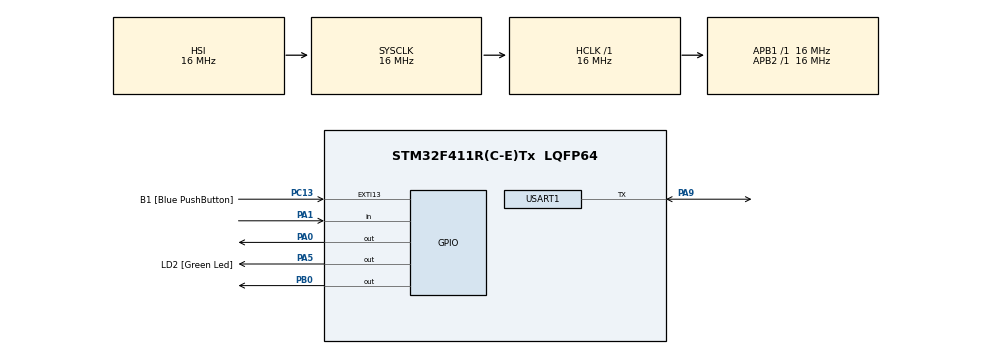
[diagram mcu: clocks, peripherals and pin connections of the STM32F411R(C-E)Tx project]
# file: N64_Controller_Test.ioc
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Mcu.Family=STM32F4
Mcu.Name=STM32F411R(C-E)Tx
Mcu.Package=LQFP64
NVIC.PriorityGroup=NVIC_PRIORITYGROUP_0
PA0-WKUP.GPIO_PuPd=GPIO_PULLUP
PA0-WKUP.Signal=GPIO_Output
PA1.GPIO_PuPd=GPIO_PULLUP
PA1.Signal=GPIO_Input
PA13.Mode=Serial_Wire
PA13.Signal=SYS_JTMS-SWDIO
PA14.Mode=Serial_Wire
PA14.Signal=SYS_JTCK-SWCLK
PA3.GPIO_Label=USART_RX
PA3.Signal=USART2_RX
PA5.GPIO_Label=LD2 [Green Led]
PA5.Signal=GPIO_Output
PA9.Mode=Half_duplex(single_wire_mode)
PA9.Signal=USART1_TX
PB0.GPIO_PuPd=GPIO_PULLUP
PB0.Signal=GPIO_Output
PB3.GPIO_Label=SWO
PB3.Signal=SYS_JTDO-SWO
PC13-ANTI_TAMP.GPIO_Label=B1 [Blue PushButton]
PC13-ANTI_TAMP.GPIO_ModeDefaultEXTI=GPIO_MODE_IT_FALLING
PC13-ANTI_TAMP.Signal=GPXTI13
PC14-OSC32_IN.Signal=RCC_OSC32_IN
PC15-OSC32_OUT.Signal=RCC_OSC32_OUT
PH0\ -\ OSC_IN.Signal=RCC_OSC_IN
PH1\ -\ OSC_OUT.Signal=RCC_OSC_OUT
ProjectManager.HeapSize=0x200
ProjectManager.StackSize=0x400
ProjectManager.TargetToolchain=STM32CubeIDE
RCC.48MHZClocksFreq_Value=50000000
RCC.AHBFreq_Value=16000000
RCC.APB1Freq_Value=16000000
RCC.APB1TimFreq_Value=16000000
RCC.APB2Freq_Value=16000000
RCC.APB2TimFreq_Value=16000000
RCC.CortexFreq_Value=16000000
RCC.DATA_CACHE_ENABLE=0
RCC.FLatency-AdvancedSettings=FLASH_LATENCY_0
RCC.HCLKFreq_Value=16000000
RCC.HSE_VALUE=8000000
RCC.HSI_VALUE=16000000
RCC.INSTRUCTION_CACHE_ENABLE=0
RCC.LSE_VALUE=32768
RCC.PLLM=8
RCC.PLLN=100
RCC.PREFETCH_ENABLE=0
RCC.SYSCLKFreq_VALUE=16000000
RCC.VCOOutputFreq_Value=200000000
USART1.BaudRate=1000000
USART1.VirtualMode=VM_ASYNC
board=NUCLEO-F411RE

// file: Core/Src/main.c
/* USER CODE BEGIN Header */
/**
  ******************************************************************************
  * @file           : main.c
  * @brief          : Main program body
  ******************************************************************************
  * @attention
  *
  * Copyright (c) 2023 STMicroelectronics.
  * All rights reserved.
  *
  * This software is licensed under terms that can be found in the LICENSE file
  * in the root directory of this software component.
  * If no LICENSE file comes with this software, it is provided AS-IS.
  *
  ******************************************************************************
  */
/* USER CODE END Header */
#include "main.h"

UART_HandleTypeDef huart1;

void SystemClock_Config(void);
static void MX_GPIO_Init(void);
static void MX_USART1_UART_Init(void);
/* USER CODE BEGIN PFP */
extern uint32_t joybus_communicate(uint32_t tx_msg); // assembly routine to bitbang n64
/* USER CODE END PFP */

int main(void)
{

  /* MCU Configuration--------------------------------------------------------*/

  /* Reset of all peripherals, Initializes the Flash interface and the Systick. */
  HAL_Init();

  /* Configure the system clock */
  SystemClock_Config();

  /* Initialize all configured peripherals */
  MX_GPIO_Init();
  MX_USART1_UART_Init();
  /* USER CODE BEGIN 2 */
  uint32_t n64_status;
  /* USER CODE END 2 */

  /* Infinite loop */
  /* USER CODE BEGIN WHILE */
  while (1)
  {
	  HAL_GPIO_WritePin(GPIOB, GPIO_PIN_0, 1);
	  n64_status = 0;
	  uint32_t tx_msg = 0xE8888888;
	  n64_status = joybus_communicate(tx_msg);
    /* USER CODE END WHILE */

  }
}

void SystemClock_Config(void)
{
  RCC_OscInitTypeDef RCC_OscInitStruct = {0};
  RCC_ClkInitTypeDef RCC_ClkInitStruct = {0};

  /** Configure the main internal regulator output voltage
  */
  __HAL_RCC_PWR_CLK_ENABLE();
  __HAL_PWR_VOLTAGESCALING_CONFIG(PWR_REGULATOR_VOLTAGE_SCALE1);

  /** Initializes the RCC Oscillators according to the specified parameters
  * in the RCC_OscInitTypeDef structure.
  */
  RCC_OscInitStruct.OscillatorType = RCC_OSCILLATORTYPE_HSI;
  RCC_OscInitStruct.HSIState = RCC_HSI_ON;
  RCC_OscInitStruct.HSICalibrationValue = RCC_HSICALIBRATION_DEFAULT;
  RCC_OscInitStruct.PLL.PLLState = RCC_PLL_NONE;
  if (HAL_RCC_OscConfig(&RCC_OscInitStruct) != HAL_OK)
  {
    Error_Handler();
  }

  /** Initializes the CPU, AHB and APB buses clocks
  */
  RCC_ClkInitStruct.ClockType = RCC_CLOCKTYPE_HCLK|RCC_CLOCKTYPE_SYSCLK
                              |RCC_CLOCKTYPE_PCLK1|RCC_CLOCKTYPE_PCLK2;
  RCC_ClkInitStruct.SYSCLKSource = RCC_SYSCLKSOURCE_HSI;
  RCC_ClkInitStruct.AHBCLKDivider = RCC_SYSCLK_DIV1;
  RCC_ClkInitStruct.APB1CLKDivider = RCC_HCLK_DIV1;
  RCC_ClkInitStruct.APB2CLKDivider = RCC_HCLK_DIV1;

  if (HAL_RCC_ClockConfig(&RCC_ClkInitStruct, FLASH_LATENCY_0) != HAL_OK)
  {
    Error_Handler();
  }
}

static void MX_USART1_UART_Init(void)
{

  huart1.Instance = USART1;
  huart1.Init.BaudRate = 1000000;
  huart1.Init.WordLength = UART_WORDLENGTH_8B;
  huart1.Init.StopBits = UART_STOPBITS_1;
  huart1.Init.Parity = UART_PARITY_NONE;
  huart1.Init.Mode = UART_MODE_TX_RX;
  huart1.Init.HwFlowCtl = UART_HWCONTROL_NONE;
  huart1.Init.OverSampling = UART_OVERSAMPLING_16;
  if (HAL_HalfDuplex_Init(&huart1) != HAL_OK)
  {
    Error_Handler();
  }

}

static void MX_GPIO_Init(void)
{
  GPIO_InitTypeDef GPIO_InitStruct = {0};

  /* GPIO Ports Clock Enable */
  __HAL_RCC_GPIOC_CLK_ENABLE();
  __HAL_RCC_GPIOH_CLK_ENABLE();
  __HAL_RCC_GPIOA_CLK_ENABLE();
  __HAL_RCC_GPIOB_CLK_ENABLE();

  /*Configure GPIO pin Output Level */
  HAL_GPIO_WritePin(GPIOA, GPIO_PIN_0|LD2_Pin, GPIO_PIN_RESET);

  /*Configure GPIO pin Output Level */
  HAL_GPIO_WritePin(GPIOB, GPIO_PIN_0, GPIO_PIN_RESET);

  /*Configure GPIO pin : B1_Pin */
  GPIO_InitStruct.Pin = B1_Pin;
  GPIO_InitStruct.Mode = GPIO_MODE_IT_FALLING;
  GPIO_InitStruct.Pull = GPIO_NOPULL;
  HAL_GPIO_Init(B1_GPIO_Port, &GPIO_InitStruct);

  /*Configure GPIO pin : PA0 */
  GPIO_InitStruct.Pin = GPIO_PIN_0;
  GPIO_InitStruct.Mode = GPIO_MODE_OUTPUT_PP;
  GPIO_InitStruct.Pull = GPIO_PULLUP;
  GPIO_InitStruct.Speed = GPIO_SPEED_FREQ_LOW;
  HAL_GPIO_Init(GPIOA, &GPIO_InitStruct);

  /*Configure GPIO pin : PA1 */
  GPIO_InitStruct.Pin = GPIO_PIN_1;
  GPIO_InitStruct.Mode = GPIO_MODE_INPUT;
  GPIO_InitStruct.Pull = GPIO_PULLUP;
  HAL_GPIO_Init(GPIOA, &GPIO_InitStruct);

  /*Configure GPIO pin : USART_RX_Pin */
  GPIO_InitStruct.Pin = USART_RX_Pin;
  GPIO_InitStruct.Mode = GPIO_MODE_AF_PP;
  GPIO_InitStruct.Pull = GPIO_NOPULL;
  GPIO_InitStruct.Speed = GPIO_SPEED_FREQ_VERY_HIGH;
  GPIO_InitStruct.Alternate = GPIO_AF7_USART2;
  HAL_GPIO_Init(USART_RX_GPIO_Port, &GPIO_InitStruct);

  /*Configure GPIO pin : LD2_Pin */
  GPIO_InitStruct.Pin = LD2_Pin;
  GPIO_InitStruct.Mode = GPIO_MODE_OUTPUT_PP;
  GPIO_InitStruct.Pull = GPIO_NOPULL;
  GPIO_InitStruct.Speed = GPIO_SPEED_FREQ_LOW;
  HAL_GPIO_Init(LD2_GPIO_Port, &GPIO_InitStruct);

  /*Configure GPIO pin : PB0 */
  GPIO_InitStruct.Pin = GPIO_PIN_0;
  GPIO_InitStruct.Mode = GPIO_MODE_OUTPUT_PP;
  GPIO_InitStruct.Pull = GPIO_PULLUP;
  GPIO_InitStruct.Speed = GPIO_SPEED_FREQ_LOW;
  HAL_GPIO_Init(GPIOB, &GPIO_InitStruct);

}

void Error_Handler(void)
{
  __disable_irq();
  while (1)
  {
  }
}
